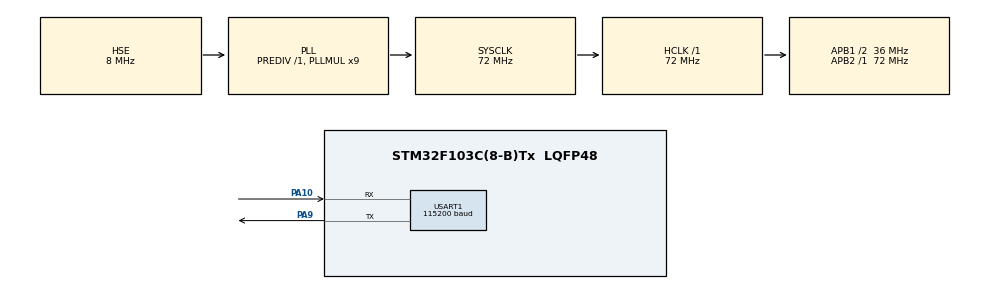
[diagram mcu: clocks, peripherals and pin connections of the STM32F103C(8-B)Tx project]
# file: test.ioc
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Dma.Request0=USART1_RX
Dma.Request1=USART1_TX
Dma.USART1_RX.0.Direction=DMA_PERIPH_TO_MEMORY
Dma.USART1_RX.0.Instance=DMA1_Channel5
Dma.USART1_RX.0.MemDataAlignment=DMA_MDATAALIGN_BYTE
Dma.USART1_RX.0.MemInc=DMA_MINC_ENABLE
Dma.USART1_RX.0.Mode=DMA_CIRCULAR
Dma.USART1_RX.0.PeriphDataAlignment=DMA_PDATAALIGN_BYTE
Dma.USART1_RX.0.PeriphInc=DMA_PINC_DISABLE
Dma.USART1_RX.0.Priority=DMA_PRIORITY_LOW
Dma.USART1_TX.1.Direction=DMA_MEMORY_TO_PERIPH
Dma.USART1_TX.1.Instance=DMA1_Channel4
Dma.USART1_TX.1.MemDataAlignment=DMA_MDATAALIGN_BYTE
Dma.USART1_TX.1.MemInc=DMA_MINC_ENABLE
Dma.USART1_TX.1.Mode=DMA_CIRCULAR
Dma.USART1_TX.1.PeriphDataAlignment=DMA_PDATAALIGN_BYTE
Dma.USART1_TX.1.PeriphInc=DMA_PINC_DISABLE
Dma.USART1_TX.1.Priority=DMA_PRIORITY_LOW
Mcu.Family=STM32F1
Mcu.Name=STM32F103C(8-B)Tx
Mcu.Package=LQFP48
NVIC.DMA1_Channel4_IRQn=true\:0\:0\:false
NVIC.DMA1_Channel5_IRQn=true\:0\:0\:false
NVIC.PriorityGroup=NVIC_PRIORITYGROUP_4
NVIC.USART1_IRQn=true\:0\:0\:false
PA10.Mode=Asynchronous
PA10.Signal=USART1_RX
PA9.Mode=Asynchronous
PA9.Signal=USART1_TX
PD0-OSC_IN.Mode=HSE-External-Oscillator
PD0-OSC_IN.Signal=RCC_OSC_IN
PD1-OSC_OUT.Mode=HSE-External-Oscillator
PD1-OSC_OUT.Signal=RCC_OSC_OUT
ProjectManager.TargetToolchain=MDK-ARM V5
RCC.ADCPresc=RCC_ADCPCLK2_DIV6
RCC.AHBFreq_Value=72000000
RCC.APB1CLKDivider=RCC_HCLK_DIV2
RCC.APB1Freq_Value=36000000
RCC.APB1TimCLKDivider=1
RCC.APB1TimFreq_Value=36000000
RCC.APB2Freq_Value=72000000
RCC.APB2TimFreq_Value=72000000
RCC.HCLKFreq_Value=72000000
RCC.HSIState=RCC_HSI_ON
RCC.PLLMUL=RCC_PLL_MUL9
RCC.PLLSourceVirtual=RCC_PLLSOURCE_HSE
RCC.SYSCLKFreq_VALUE=72000000
RCC.SYSCLKSource=RCC_SYSCLKSOURCE_PLLCLK
RCC.USBFreq_Value=72000000
USART1.BaudRate=115200
board=test

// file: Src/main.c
/**
  ******************************************************************************
  * File Name          : main.c
  * Description        : Main program body
  ******************************************************************************
  *
  * COPYRIGHT(c) 2016 STMicroelectronics
  *
  * Redistribution and use in source and binary forms, with or without modification,
  * are permitted provided that the following conditions are met:
  *   1. Redistributions of source code must retain the above copyright notice,
  *      this list of conditions and the following disclaimer.
  *   2. Redistributions in binary form must reproduce the above copyright notice,
  *      this list of conditions and the following disclaimer in the documentation
  *      and/or other materials provided with the distribution.
  *   3. Neither the name of STMicroelectronics nor the names of its contributors
  *      may be used to endorse or promote products derived from this software
  *      without specific prior written permission.
  *
  * THIS SOFTWARE IS PROVIDED BY THE COPYRIGHT HOLDERS AND CONTRIBUTORS "AS IS"
  * AND ANY EXPRESS OR IMPLIED WARRANTIES, INCLUDING, BUT NOT LIMITED TO, THE
  * IMPLIED WARRANTIES OF MERCHANTABILITY AND FITNESS FOR A PARTICULAR PURPOSE ARE
  * DISCLAIMED. IN NO EVENT SHALL THE COPYRIGHT HOLDER OR CONTRIBUTORS BE LIABLE
  * FOR ANY DIRECT, INDIRECT, INCIDENTAL, SPECIAL, EXEMPLARY, OR CONSEQUENTIAL
  * DAMAGES (INCLUDING, BUT NOT LIMITED TO, PROCUREMENT OF SUBSTITUTE GOODS OR
  * SERVICES; LOSS OF USE, DATA, OR PROFITS; OR BUSINESS INTERRUPTION) HOWEVER
  * CAUSED AND ON ANY THEORY OF LIABILITY, WHETHER IN CONTRACT, STRICT LIABILITY,
  * OR TORT (INCLUDING NEGLIGENCE OR OTHERWISE) ARISING IN ANY WAY OUT OF THE USE
  * OF THIS SOFTWARE, EVEN IF ADVISED OF THE POSSIBILITY OF SUCH DAMAGE.
  *
  ******************************************************************************
  */
#include "stm32f1xx_hal.h"
#include "dma.h"
#include "usart.h"
#include "gpio.h"

/* USER CODE BEGIN Includes */
#include <stdio.h>
#include <stdarg.h>
#include <stdlib.h>

#define MAXSIZE 1024
#define __HAL_DMA_SET_COUNTER(__HANDLE__, __COUNTER__) ((__HANDLE__)->Instance->CNDTR = (uint16_t)(__COUNTER__))/* USER CODE END Includes */

/* USER CODE END Includes */

/* USER CODE BEGIN PV */
/* Private variables ---------------------------------------------------------*/
extern UART_HandleTypeDef huart1;
extern DMA_HandleTypeDef hdma_usart1_rx;
extern DMA_HandleTypeDef hdma_usart1_tx;

uint8_t * RX_DATA1[100];
uint8_t RX_DATA[MAXSIZE*2]={0};
uint16_t RX_NUM=0,times=0;
volatile uint8_t okflag=1;
volatile uint8_t firstflag=0;

/* USER CODE END PV */

void SystemClock_Config(void);

/* USER CODE BEGIN PFP */
/* Private function prototypes -----------------------------------------------*/

/* USER CODE END PFP */

int main(void)
{

  /* MCU Configuration----------------------------------------------------------*/

  /* Reset of all peripherals, Initializes the Flash interface and the Systick. */
  HAL_Init();

  /* Configure the system clock */
  SystemClock_Config();

  /* Initialize all configured peripherals */
  MX_GPIO_Init();
  MX_DMA_Init();
  MX_USART1_UART_Init();

  /* USER CODE BEGIN 2 */
		HAL_UART_Receive_DMA(&huart1,RX_DATA,MAXSIZE);
	__HAL_UART_ENABLE_IT(&huart1,UART_IT_IDLE);

  /* USER CODE END 2 */

  /* Infinite loop */
  while (1)
  {

		if(RX_NUM)
	{

		HAL_UART_Transmit_DMA(&huart1,RX_DATA,RX_NUM); //把接收到的字节再发送到串口1

		RX_NUM=0;

		}
  }

}

/** System Clock Configuration
*/
void SystemClock_Config(void)
{

  RCC_OscInitTypeDef RCC_OscInitStruct;
  RCC_ClkInitTypeDef RCC_ClkInitStruct;

  RCC_OscInitStruct.OscillatorType = RCC_OSCILLATORTYPE_HSE;
  RCC_OscInitStruct.HSEState = RCC_HSE_ON;
  RCC_OscInitStruct.HSEPredivValue = RCC_HSE_PREDIV_DIV1;
  RCC_OscInitStruct.PLL.PLLState = RCC_PLL_ON;
  RCC_OscInitStruct.PLL.PLLSource = RCC_PLLSOURCE_HSE;
  RCC_OscInitStruct.PLL.PLLMUL = RCC_PLL_MUL9;
  HAL_RCC_OscConfig(&RCC_OscInitStruct);

  RCC_ClkInitStruct.ClockType = RCC_CLOCKTYPE_SYSCLK|RCC_CLOCKTYPE_PCLK1;
  RCC_ClkInitStruct.SYSCLKSource = RCC_SYSCLKSOURCE_PLLCLK;
  RCC_ClkInitStruct.AHBCLKDivider = RCC_SYSCLK_DIV1;
  RCC_ClkInitStruct.APB1CLKDivider = RCC_HCLK_DIV2;
  RCC_ClkInitStruct.APB2CLKDivider = RCC_HCLK_DIV1;
  HAL_RCC_ClockConfig(&RCC_ClkInitStruct, FLASH_LATENCY_2);

  HAL_SYSTICK_Config(HAL_RCC_GetHCLKFreq()/1000);

  HAL_SYSTICK_CLKSourceConfig(SYSTICK_CLKSOURCE_HCLK);

  /* SysTick_IRQn interrupt configuration */
  HAL_NVIC_SetPriority(SysTick_IRQn, 0, 0);
}

/* USER CODE BEGIN 4 */
void HAL_UART_RxCpltCallback(UART_HandleTypeDef *huart)  //接收完成
{

}

void HAL_UART_TxCpltCallback(UART_HandleTypeDef *huart)  //发送完成
{

	huart1.State=HAL_UART_STATE_READY;
	okflag=1;
}
/******************算定义PRINTF函数*********************/

/* USER CODE END 4 */

/************************ (C) COPYRIGHT STMicroelectronics *****END OF FILE****/
